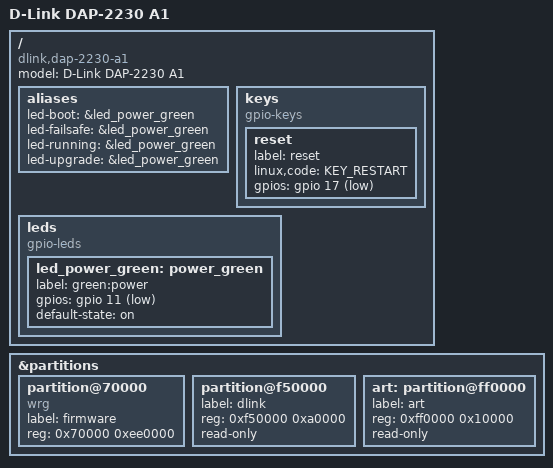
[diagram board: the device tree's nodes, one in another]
// SPDX-License-Identifier: GPL-2.0-or-later OR MIT

#include "qca953x_dlink_dap-2xxx.dtsi"

/ {
	compatible = "dlink,dap-2230-a1", "qca,qca9533";
	model = "D-Link DAP-2230 A1";

	aliases {
		led-boot = &led_power_green;
		led-failsafe = &led_power_green;
		led-running = &led_power_green;
		led-upgrade = &led_power_green;
	};

	keys {
		compatible = "gpio-keys";

		reset {
			label = "reset";
			linux,code = <KEY_RESTART>;
			gpios = <&gpio 17 GPIO_ACTIVE_LOW>;
		};
	};

	leds {
		compatible = "gpio-leds";

		led_power_green: power_green {
			label = "green:power";
			gpios = <&gpio 11 GPIO_ACTIVE_LOW>;
			default-state = "on";
		};
	};
};

&partitions {
	partition@70000 {
		label = "firmware";
		reg = <0x70000 0xee0000>;
		compatible = "wrg";
	};

	partition@f50000 {
		label = "dlink";
		reg = <0xf50000 0xa0000>;
		read-only;
	};

	art: partition@ff0000 {
		label = "art";
		reg = <0xff0000 0x10000>;
		read-only;
	};
};
